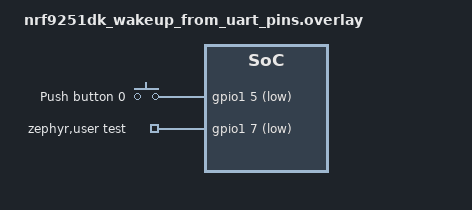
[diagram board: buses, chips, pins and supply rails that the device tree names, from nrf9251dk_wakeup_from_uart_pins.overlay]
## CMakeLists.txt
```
#
# Copyright (c) 2024 Nordic Semiconductor ASA
#
# SPDX-License-Identifier: LicenseRef-Nordic-5-Clause
#

cmake_minimum_required(VERSION 3.20.0)

find_package(Zephyr REQUIRED HINTS $ENV{ZEPHYR_BASE})

if(NOT SYSBUILD)
  message(FATAL_ERROR
    " This is a multi-image application that should be built using sysbuild.\n"
    " Add --sysbuild argument to west build command to prepare all the images."
  )
endif()

project(idle_gpio)

target_sources(app PRIVATE src/main.c)
```

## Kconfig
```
#
# Copyright (c) 2026 Nordic Semiconductor ASA
#
# SPDX-License-Identifier: LicenseRef-Nordic-5-Clause
#

config GPIOTE_LATENCY_LOWPOWER
	bool "Set GPIOTE latency to low power"

source "Kconfig.zephyr"
```

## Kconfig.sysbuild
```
#
# Copyright (c) 2024 Nordic Semiconductor ASA
#
# SPDX-License-Identifier: LicenseRef-Nordic-5-Clause
#

choice NETCORE
	default NETCORE_REMOTE

config NETCORE_REMOTE
	bool "Remote image"

config NETCORE_WAKEUP_TRIGGER
	bool "Wakeup trigger image"

config NETCORE_REMOTE_SLEEP_FOREVER
	bool "Remote sleep forever image"

endchoice

config NETCORE_IMAGE_NAME
	default "remote" if NETCORE_REMOTE
	default "wakeup_trigger" if NETCORE_WAKEUP_TRIGGER
	default "remote_sleep_forever" if NETCORE_REMOTE_SLEEP_FOREVER

config NETCORE_IMAGE_PATH
	default "$(ZEPHYR_NRF_MODULE_DIR)/tests/benchmarks/multicore/idle_gpio/remote" if NETCORE_REMOTE
	default "$(ZEPHYR_NRF_MODULE_DIR)/tests/benchmarks/multicore/idle_gpio/wakeup_trigger" if NETCORE_WAKEUP_TRIGGER
	default "$(ZEPHYR_NRF_MODULE_DIR)/tests/benchmarks/power_consumption/common/remote_sleep_forever" if NETCORE_REMOTE_SLEEP_FOREVER

choice PPRCORE
	default PPRCORE_NONE

config PPRCORE_REMOTE
	bool "Remote image"

endchoice

config PPRCORE_IMAGE_NAME
	default "remote" if PPRCORE_REMOTE

config PPRCORE_IMAGE_PATH
	default "$(ZEPHYR_NRF_MODULE_DIR)/tests/benchmarks/multicore/idle_gpio/remote" if PPRCORE_REMOTE

source "share/sysbuild/Kconfig"
```

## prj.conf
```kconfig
CONFIG_PRINTK=y
CONFIG_LOG=y
```

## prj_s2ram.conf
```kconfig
CONFIG_PM=y
CONFIG_POWEROFF=y
# CONFIG_CONSOLE=n
# CONFIG_UART_CONSOLE=n
# CONFIG_SERIAL=n
CONFIG_GPIO=y
# CONFIG_BOOT_BANNER=n
# CONFIG_NCS_BOOT_BANNER=n
```

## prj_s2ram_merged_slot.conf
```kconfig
CONFIG_PM=y
CONFIG_POWEROFF=y
CONFIG_CONSOLE=n
CONFIG_UART_CONSOLE=n
CONFIG_SERIAL=n
CONFIG_GPIO=y
CONFIG_BOOT_BANNER=n
CONFIG_NCS_BOOT_BANNER=n
```

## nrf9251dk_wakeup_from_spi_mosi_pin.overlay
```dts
/*
 * Copyright (c) 2026 Nordic Semiconductor ASA
 *
 * SPDX-License-Identifier: LicenseRef-Nordic-5-Clause
 */

/* Delete LED3 on P2.09 as that GPIO is used as a button0. */
/ {
	aliases {
		/delete-property/ led3;
	};
};

/delete-node/ &led3;

/ {
	/*
	 * Redefine sw0/button0 to use P2.03 (SPI MOSI) to P2.09 (button0) loopback.
	 * Thus, when "remote" starts SPI transfer, there will be gpio interrupt,
	 * the same as originally triggered by sw0 button.
	 * P2.03 - P2.09 loopback is needed.
	 */
	buttons {
		compatible = "gpio-keys";

		button0: button_0 {
			gpios = <&gpio2 9 (GPIO_PULL_DOWN | GPIO_ACTIVE_HIGH)>;
			label = "Push button 0";
			zephyr,code = <INPUT_KEY_0>;
		};
	};
};

&spi131 {
	status = "reserved";
	interrupt-parent = <&cpuppr_clic>;
};

&gpio2 {
	status = "okay";
};
```

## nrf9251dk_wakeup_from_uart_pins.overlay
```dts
/*
 * Copyright (c) 2026 Nordic Semiconductor ASA
 *
 * SPDX-License-Identifier: LicenseRef-Nordic-5-Clause
 */

/ {
	/*
	 * Redefine sw0/button0 to use RXD0 - P1.05
	 * Thus, when sending character from host, there will be gpio interrupt,
	 * the same as originally triggered by sw0 button.
	 */
	buttons {
		compatible = "gpio-keys";

		button0: button_0 {
			gpios = <&gpio1 5 (GPIO_PULL_UP | GPIO_ACTIVE_LOW)>;
			label = "Push button 0";
			zephyr,code = <INPUT_KEY_0>;
		};
	};

	zephyr,user {
		test-gpios = <&gpio1 7 GPIO_ACTIVE_LOW>;
	};
};

&gpio1 {
	status = "okay";
};

&uart133 {
	status = "disabled";
};

&uart132 {
	status = "disabled";
};
```

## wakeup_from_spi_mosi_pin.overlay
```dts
/*
 * Copyright (c) 2026 Nordic Semiconductor ASA
 *
 * SPDX-License-Identifier: LicenseRef-Nordic-5-Clause
 */

/ {
	/*
	 * Redefine sw0/button0 to use SPI MOSI - P0.06
	 * Thus, when "remote" starts SPI transfer, there will be gpio interrupt,
	 * the same as originally triggered by sw0 button.
	 * P0.06 - P0.07 loopback is needed.
	 */
	buttons {
		compatible = "gpio-keys";

		button0: button_0 {
			gpios = <&gpio0 6 (GPIO_PULL_DOWN | GPIO_ACTIVE_HIGH)>;
			label = "Push button 0";
			zephyr,code = <INPUT_KEY_0>;
		};
	};
};
```

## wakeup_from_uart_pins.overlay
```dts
/*
 * Copyright (c) 2024 Nordic Semiconductor ASA
 *
 * SPDX-License-Identifier: LicenseRef-Nordic-5-Clause
 */

/ {
	/*
	 * Redefine sw0/button0 to use RXD0 - P2.04
	 * Thus, when sending character from host, there will be gpio interrupt,
	 * the same as originally triggered by sw0 button.
	 */
	buttons {
		compatible = "gpio-keys";

		button0: button_0 {
			gpios = <&gpio2 4 (GPIO_PULL_UP | GPIO_ACTIVE_LOW)>;
			label = "Push button 0";
			zephyr,code = <INPUT_KEY_0>;
		};
	};

	zephyr,user {
		test-gpios = <&gpio2 7 GPIO_ACTIVE_LOW>;
	};
};

&gpio2 {
	status = "okay";
};

&uart135 {
	status = "disabled";
};
```

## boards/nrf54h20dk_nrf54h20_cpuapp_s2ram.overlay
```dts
/*
 * Copyright (c) 2024 Nordic Semiconductor ASA
 *
 * SPDX-License-Identifier: LicenseRef-Nordic-5-Clause
 */

/ {
	aliases {
		/delete-property/ sw1;
		/delete-property/ led1;
	};
};

/delete-node/ &button1;
/delete-node/ &led1;

&gpiote130 {
	status = "okay";
	owned-channels = <0>;
};

&gpio6 {
	status = "disabled";
};

&exmif {
	status = "disabled";
};
```

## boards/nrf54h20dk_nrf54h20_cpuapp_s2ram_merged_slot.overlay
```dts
/*
 * Copyright (c) 2025 Nordic Semiconductor ASA
 *
 * SPDX-License-Identifier: LicenseRef-Nordic-5-Clause
 */

#include "nrf54h20dk_nrf54h20_cpuapp_s2ram.overlay"
#include "../sysbuild/nrf54h20dk_nrf54h20_memory_map_merged_slot.dtsi"

secondary_app_partition: &cpuapp_slot1_partition {};
```

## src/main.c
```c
/*
 * Copyright (c) 2024 Nordic Semiconductor ASA
 *
 * SPDX-License-Identifier: LicenseRef-Nordic-5-Clause
 */

#include <hal/nrf_gpiote.h>
#include <zephyr/kernel.h>
#include <zephyr/logging/log.h>
#include <zephyr/drivers/gpio.h>
#include <zephyr/drivers/gpio/gpio_nrf.h>
#include <zephyr/pm/pm.h>

LOG_MODULE_REGISTER(idle_gpio);

#if IS_ENABLED(CONFIG_SOC_NRF54H20_CPUAPP) || IS_ENABLED(CONFIG_SOC_NRF9251_CPUAPP)
#define SW_NODE	 DT_ALIAS(sw0)
#define LED_NODE DT_ALIAS(led0)
#elif IS_ENABLED(CONFIG_SOC_NRF54H20_CPURAD) || IS_ENABLED(CONFIG_SOC_NRF54H20_CPUPPR) || \
	IS_ENABLED(CONFIG_SOC_NRF9251_CPUPPR)
#define SW_NODE	 DT_ALIAS(sw1)
#define LED_NODE DT_ALIAS(led1)
#else
#error "Invalid core selected. "
#endif

#define SW_GPIO_CTLR   DT_GPIO_CTLR(SW_NODE, gpios)
#define SW_GPIOTE_NODE DT_PHANDLE(SW_GPIO_CTLR, gpiote_instance)
#define SW_GPIO_INT_FLAGS                                                                          \
	(DT_PROP(SW_GPIOTE_NODE, no_port_event) ? GPIO_INT_EDGE_FALLING : GPIO_INT_LEVEL_ACTIVE)

#if IS_ENABLED(CONFIG_SOC_NRF54H20_CPUPPR) || IS_ENABLED(CONFIG_SOC_NRF9251_CPUPPR)
#include <ironside_zephyr/se/uicr_periphconf.h>

/* The input pin must be configured as NS to be allowed to trigger PPR's GPIOTE IRQ. */
UICR_PERIPHCONF_ENTRY(PERIPHCONF_SPU_FEATURE_GPIO_PIN(NRF_SPU131, DT_PROP(SW_GPIO_CTLR, port),
						      DT_GPIO_PIN(SW_NODE, gpios), /* NS */ false,
						      NRF_OWNER_APPLICATION, /* LOCK */ true));
#endif

static const struct gpio_dt_spec sw = GPIO_DT_SPEC_GET(SW_NODE, gpios);
static const struct gpio_dt_spec led = GPIO_DT_SPEC_GET(LED_NODE, gpios);

#if DT_NODE_EXISTS(DT_PATH(zephyr_user))
static const struct gpio_dt_spec fake_rts = GPIO_DT_SPEC_GET(DT_PATH(zephyr_user), test_gpios);
#endif

static K_SEM_DEFINE(my_gpio_sem, 0, 1);

void my_gpio_callback(const struct device *dev, struct gpio_callback *cb, uint32_t pins)
{
	gpio_pin_set_dt(&led, 1);
	LOG_INF("User callback for %s", CONFIG_BOARD_TARGET);
	k_sem_give(&my_gpio_sem);
}

static struct gpio_callback gpio_cb;

int main(void)
{
	unsigned int cnt = 0;
	int rc;

	rc = gpio_is_ready_dt(&led);
	if (rc < 0) {
		LOG_ERR("GPIO Device not ready (%d)", rc);
		return 0;
	}

	rc = gpio_pin_configure_dt(&led, GPIO_OUTPUT_ACTIVE);
	if (rc < 0) {
		LOG_ERR("Could not configure led GPIO (%d)", rc);
		return 0;
	}

#if DT_NODE_EXISTS(DT_PATH(zephyr_user))
	rc = gpio_is_ready_dt(&fake_rts);
	if (rc < 0) {
		LOG_ERR("GPIO Device not ready (%d)", rc);
		return 0;
	}

	rc = gpio_pin_configure_dt(&fake_rts, GPIO_OUTPUT_ACTIVE);
	if (rc < 0) {
		LOG_ERR("Could not configure fake_rst GPIO (%d)", rc);
		return 0;
	}
#endif

	rc = gpio_is_ready_dt(&sw);
	if (rc < 0) {
		LOG_ERR("GPIO Device not ready (%d)", rc);
		return 0;
	}

	rc = gpio_pin_configure_dt(&sw, GPIO_INPUT);
	if (rc < 0) {
		LOG_ERR("Could not configure sw GPIO (%d)", rc);
		return 0;
	}

#if IS_ENABLED(CONFIG_TEST_GPIOTE_LATENCY_LOWPOWER)
	NRF_GPIOTE_Type * gpiote_reg = gpio_nrf_gpiote_by_port_get(sw.port);

	nrf_gpiote_latency_set(gpiote_reg, NRF_GPIOTE_LATENCY_LOWPOWER);
	LOG_INF("GPIOTE latency set to: %u", nrf_gpiote_latency_get(gpiote_reg));
#endif

	rc = gpio_pin_interrupt_configure(sw.port, sw.pin, SW_GPIO_INT_FLAGS);

	if (rc < 0) {
		LOG_ERR("Could not configure sw GPIO interrupt (%d)", rc);
		return 0;
	}
	gpio_init_callback(&gpio_cb, my_gpio_callback, 0xFFFF);
	gpio_add_callback(sw.port, &gpio_cb);
	LOG_INF("Multicore idle_gpio test on %s", CONFIG_BOARD_TARGET);
	while (1) {
		LOG_INF("Multicore idle_gpio test iteration %u", cnt++);
		gpio_pin_set_dt(&led, 0);
		if (k_sem_take(&my_gpio_sem, K_FOREVER) != 0) {
			LOG_ERR("Failed to take a semaphore");
			return 0;
		}
		k_busy_wait(1000000);
		/* De-bounce when button is used. Reset a semaphores count to 0. */
		k_sem_reset(&my_gpio_sem);
	}

	return 0;
}
```
